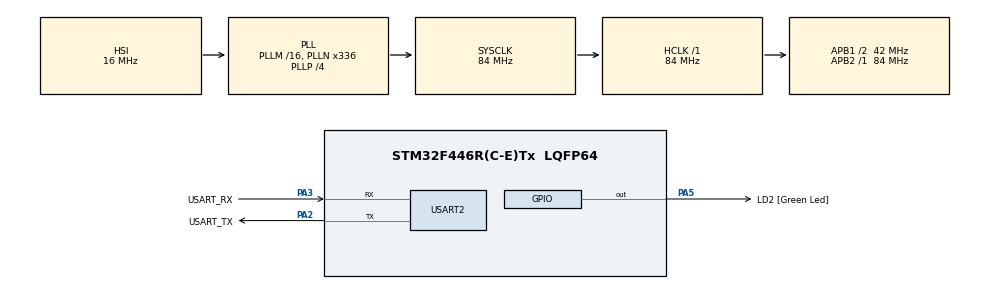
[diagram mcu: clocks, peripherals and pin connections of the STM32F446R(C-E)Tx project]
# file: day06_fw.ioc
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Mcu.Family=STM32F4
Mcu.Name=STM32F446R(C-E)Tx
Mcu.Package=LQFP64
NVIC.PriorityGroup=NVIC_PRIORITYGROUP_0
NVIC.USART2_IRQn=true\:0\:0\:false\:false\:true\:true\:true\:true
PA2.GPIO_Label=USART_TX
PA2.Mode=Asynchronous
PA2.Signal=USART2_TX
PA3.GPIO_Label=USART_RX
PA3.Mode=Asynchronous
PA3.Signal=USART2_RX
PA5.GPIO_Label=LD2 [Green Led]
PA5.Signal=GPIO_Output
ProjectManager.HeapSize=0x200
ProjectManager.StackSize=0x400
ProjectManager.TargetToolchain=STM32CubeIDE
RCC.48MHZClocksFreq_Value=84000000
RCC.AHBFreq_Value=84000000
RCC.APB1CLKDivider=RCC_HCLK_DIV2
RCC.APB1Freq_Value=42000000
RCC.APB1TimFreq_Value=84000000
RCC.APB2Freq_Value=84000000
RCC.APB2TimFreq_Value=84000000
RCC.CortexFreq_Value=84000000
RCC.FLatency-AdvancedSettings=FLASH_LATENCY_2
RCC.HCLKFreq_Value=84000000
RCC.HSE_VALUE=8000000
RCC.HSI_VALUE=16000000
RCC.PLLN=336
RCC.PLLP=RCC_PLLP_DIV4
RCC.SYSCLKFreq_VALUE=84000000
RCC.SYSCLKSource=RCC_SYSCLKSOURCE_PLLCLK
RCC.USBFreq_Value=168000000
RCC.VCOOutputFreq_Value=336000000
USART2.VirtualMode=VM_ASYNC
board=NUCLEO-F446RE

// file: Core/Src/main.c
/* USER CODE BEGIN Header */
/**
  ******************************************************************************
  * @file           : main.c
  * @brief          : Main program body
  ******************************************************************************
  * @attention
  *
  * Copyright (c) 2025 STMicroelectronics.
  * All rights reserved.
  *
  * This software is licensed under terms that can be found in the LICENSE file
  * in the root directory of this software component.
  * If no LICENSE file comes with this software, it is provided AS-IS.
  *
  ******************************************************************************
  */
/* USER CODE END Header */
#include "main.h"
#include "cbuf.h"
#include <stdarg.h>
#include <stdio.h>
#include <string.h>
#include <stdint.h>

/* USER CODE BEGIN PD */

#define BUF_SIZE 512
/* USER CODE END PD */

UART_HandleTypeDef huart2;
static volatile uint8_t tx_busy = 0;
static CircularBuffer cb;
static uint16_t inflight_len = 0;
static uint8_t tx_chunk[128];
static uint8_t rx;

void SystemClock_Config(void);
static void MX_GPIO_Init(void);
static void MX_USART2_UART_Init(void);
/* USER CODE BEGIN PFP */

static void uart2_kick_tx(void);
static void cb_enqueue_drop_oldest(CircularBuffer *q, int v);

/* USER CODE END PFP */

/* USER CODE BEGIN 0 */
/**
 * @brief  Retargets printf to UART.
 * @param  fmt: format string
 * @param  ...: variadic args
 * @retval number of bytes transmitted
 * @constraints: Non-blocking, CR-LF line endings
 */
int uart_printf(const char *fmt, ...) {
    char buf[BUF_SIZE];

    va_list ap;
    va_start(ap, fmt);
    int n = vsnprintf(buf, sizeof(buf), fmt, ap);
    va_end(ap);

    if (n <= 0) return 0;
    if (n > (int)sizeof(buf)) n = (int)sizeof(buf);  // truncate

    int enq = 0;
    // Enqueue bytes, converting '\n' -> "\r\n"
    for (int i = 0; i < n; i++) {
        unsigned char c = (unsigned char)buf[i];
        if (c == '\n') {
            // drop-oldest policy so logging never blocks
            cb_enqueue_drop_oldest(&cb, '\r');
            cb_enqueue_drop_oldest(&cb, '\n');
            enq += 2;
        } else {
            cb_enqueue_drop_oldest(&cb, c);
            enq += 1;
        }
    }

    __disable_irq();
    uart2_kick_tx();   // start/continue TX if idle
    __enable_irq();

    return enq;  // bytes queued after CRLF expansion
}

// Never block: if full, drop oldest to make space (change policy if you prefer blocking)
static void cb_enqueue_drop_oldest(CircularBuffer *q, int v) {
    if (!cb_enqueue(q, v)) {
        int dummy;
        (void)cb_dequeue(q, &dummy);
        (void)cb_enqueue(q, v);
    }
}

// Build a contiguous chunk from your FIFO and send via HAL IT
static void uart2_kick_tx(void) {
    if (tx_busy) return;
    if (cb_is_empty(&cb)) return;

    uint16_t n = 0;
    int v;

    __disable_irq();
    while (n < sizeof(tx_chunk) && cb_dequeue(&cb, &v)) {
        tx_chunk[n++] = (uint8_t)v;
    }
    __enable_irq();

    if (n == 0) return;

    inflight_len = n;
    tx_busy = 1;
    HAL_UART_Transmit_IT(&huart2, tx_chunk, n);
}

/* USER CODE END 0 */

int main(void)
{

  /* MCU Configuration--------------------------------------------------------*/

  /* Reset of all peripherals, Initializes the Flash interface and the Systick. */
  HAL_Init();

  /* Configure the system clock */
  SystemClock_Config();

  /* Initialize all configured peripherals */
  MX_GPIO_Init();
  MX_USART2_UART_Init();
  /* USER CODE BEGIN 2 */

  // initialize the circular buffer
  cb_init(&cb, BUF_SIZE);
  HAL_UART_Receive_IT(&huart2, &rx, 1);

  uart_printf("Hello world\n");

  /* USER CODE END 2 */

  /* Infinite loop */
  while (1)
  {
	  uart_printf("Counter: %lu\n", HAL_GetTick()); // prints system tick in ms
	  HAL_Delay(250);

  }
}

void SystemClock_Config(void)
{
  RCC_OscInitTypeDef RCC_OscInitStruct = {0};
  RCC_ClkInitTypeDef RCC_ClkInitStruct = {0};

  /** Configure the main internal regulator output voltage
  */
  __HAL_RCC_PWR_CLK_ENABLE();
  __HAL_PWR_VOLTAGESCALING_CONFIG(PWR_REGULATOR_VOLTAGE_SCALE3);

  /** Initializes the RCC Oscillators according to the specified parameters
  * in the RCC_OscInitTypeDef structure.
  */
  RCC_OscInitStruct.OscillatorType = RCC_OSCILLATORTYPE_HSI;
  RCC_OscInitStruct.HSIState = RCC_HSI_ON;
  RCC_OscInitStruct.HSICalibrationValue = RCC_HSICALIBRATION_DEFAULT;
  RCC_OscInitStruct.PLL.PLLState = RCC_PLL_ON;
  RCC_OscInitStruct.PLL.PLLSource = RCC_PLLSOURCE_HSI;
  RCC_OscInitStruct.PLL.PLLM = 16;
  RCC_OscInitStruct.PLL.PLLN = 336;
  RCC_OscInitStruct.PLL.PLLP = RCC_PLLP_DIV4;
  RCC_OscInitStruct.PLL.PLLQ = 2;
  RCC_OscInitStruct.PLL.PLLR = 2;
  if (HAL_RCC_OscConfig(&RCC_OscInitStruct) != HAL_OK)
  {
    Error_Handler();
  }

  /** Initializes the CPU, AHB and APB buses clocks
  */
  RCC_ClkInitStruct.ClockType = RCC_CLOCKTYPE_HCLK|RCC_CLOCKTYPE_SYSCLK
                              |RCC_CLOCKTYPE_PCLK1|RCC_CLOCKTYPE_PCLK2;
  RCC_ClkInitStruct.SYSCLKSource = RCC_SYSCLKSOURCE_PLLCLK;
  RCC_ClkInitStruct.AHBCLKDivider = RCC_SYSCLK_DIV1;
  RCC_ClkInitStruct.APB1CLKDivider = RCC_HCLK_DIV2;
  RCC_ClkInitStruct.APB2CLKDivider = RCC_HCLK_DIV1;

  if (HAL_RCC_ClockConfig(&RCC_ClkInitStruct, FLASH_LATENCY_2) != HAL_OK)
  {
    Error_Handler();
  }
}

static void MX_USART2_UART_Init(void)
{

  huart2.Instance = USART2;
  huart2.Init.BaudRate = 115200;
  huart2.Init.WordLength = UART_WORDLENGTH_8B;
  huart2.Init.StopBits = UART_STOPBITS_1;
  huart2.Init.Parity = UART_PARITY_NONE;
  huart2.Init.Mode = UART_MODE_TX_RX;
  huart2.Init.HwFlowCtl = UART_HWCONTROL_NONE;
  huart2.Init.OverSampling = UART_OVERSAMPLING_16;
  if (HAL_UART_Init(&huart2) != HAL_OK)
  {
    Error_Handler();
  }

}

static void MX_GPIO_Init(void)
{
  GPIO_InitTypeDef GPIO_InitStruct = {0};

  /* GPIO Ports Clock Enable */
  __HAL_RCC_GPIOA_CLK_ENABLE();

  /*Configure GPIO pin Output Level */
  HAL_GPIO_WritePin(LD2_GPIO_Port, LD2_Pin, GPIO_PIN_RESET);

  /*Configure GPIO pin : LD2_Pin */
  GPIO_InitStruct.Pin = LD2_Pin;
  GPIO_InitStruct.Mode = GPIO_MODE_OUTPUT_PP;
  GPIO_InitStruct.Pull = GPIO_NOPULL;
  GPIO_InitStruct.Speed = GPIO_SPEED_FREQ_LOW;
  HAL_GPIO_Init(LD2_GPIO_Port, &GPIO_InitStruct);

}

/* USER CODE BEGIN 4 */
/**
 * @brief  UART receive complete callback.
 * @param  huart: UART handle
 * @retval none
 */
void HAL_UART_RxCpltCallback(UART_HandleTypeDef *huart) {
	// make sure the callback comes from our UART handle
	if (huart == &huart2) {
		// the callback will disarm itself, so we need to rearm it
		HAL_UART_Receive_IT(&huart2, rx, 1);
	}
}

void HAL_UART_TxCpltCallback(UART_HandleTypeDef *huart) {
    if (huart == &huart2) {
        tx_busy = 0;
        inflight_len = 0;
        uart2_kick_tx();  // immediately continue with next chunk if queued
    }
}

/**
 * @brief  Processes buffered UART data.
 * @param  none
 * @retval none
 * @constraints: Disable interrupts when accessing head/tail indices or use volatile
 */
void UART_ProcessBuffer(void) {
	int ret;

	if (!cb_is_empty(&cb)) {
		cb_dequeue(&cb, &ret);
		uart_printf("Dequeued %d", ret);
	}
}

/* USER CODE END 4 */

void Error_Handler(void)
{
  __disable_irq();
  while (1)
  {
  }
}
